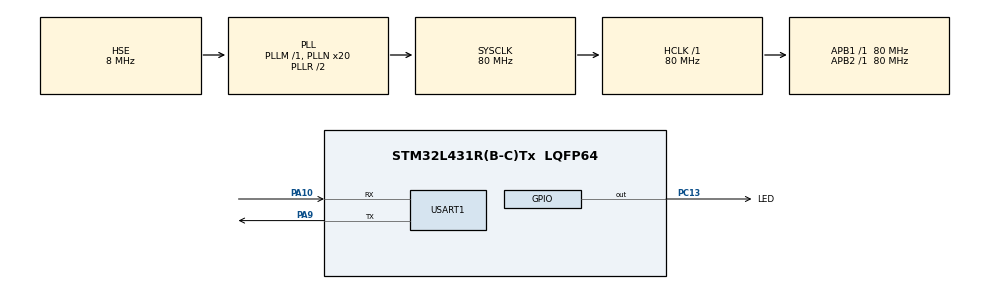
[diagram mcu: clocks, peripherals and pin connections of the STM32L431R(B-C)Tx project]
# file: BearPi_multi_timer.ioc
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Mcu.Family=STM32L4
Mcu.Name=STM32L431R(B-C)Tx
Mcu.Package=LQFP64
NVIC.PriorityGroup=NVIC_PRIORITYGROUP_4
PA10.Mode=Asynchronous
PA10.Signal=USART1_RX
PA13\ (JTMS-SWDIO).Mode=Serial_Wire
PA13\ (JTMS-SWDIO).Signal=SYS_JTMS-SWDIO
PA14\ (JTCK-SWCLK).Mode=Serial_Wire
PA14\ (JTCK-SWCLK).Signal=SYS_JTCK-SWCLK
PA9.Mode=Asynchronous
PA9.Signal=USART1_TX
PC13.GPIO_Label=LED
PC13.GPIO_Speed=GPIO_SPEED_FREQ_LOW
PC13.Signal=GPIO_Output
PH0-OSC_IN\ (PH0).Mode=HSE-External-Oscillator
PH0-OSC_IN\ (PH0).Signal=RCC_OSC_IN
PH1-OSC_OUT\ (PH1).Mode=HSE-External-Oscillator
PH1-OSC_OUT\ (PH1).Signal=RCC_OSC_OUT
ProjectManager.HeapSize=0x200
ProjectManager.StackSize=0x400
ProjectManager.TargetToolchain=MDK-ARM V5
RCC.ADCFreq_Value=32000000
RCC.AHBFreq_Value=80000000
RCC.APB1Freq_Value=80000000
RCC.APB1TimFreq_Value=80000000
RCC.APB2Freq_Value=80000000
RCC.APB2TimFreq_Value=80000000
RCC.CortexFreq_Value=80000000
RCC.HCLKFreq_Value=80000000
RCC.HSE_VALUE=8000000
RCC.HSI48_VALUE=48000000
RCC.HSI_VALUE=16000000
RCC.LSE_VALUE=32768
RCC.MSI_VALUE=4000000
RCC.PLLN=20
RCC.PLLSourceVirtual=RCC_PLLSOURCE_HSE
RCC.SYSCLKFreq_VALUE=80000000
RCC.SYSCLKSource=RCC_SYSCLKSOURCE_PLLCLK
RCC.VCOOutputFreq_Value=160000000
USART1.VirtualMode-Asynchronous=VM_ASYNC
board=custom

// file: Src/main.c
/* USER CODE BEGIN Header */
/**
  ******************************************************************************
  * @file           : main.c
  * @brief          : Main program body
  ******************************************************************************
  * @attention
  *
  * <h2><center>&copy; Copyright (c) 2020 STMicroelectronics.
  * All rights reserved.</center></h2>
  *
  * This software component is licensed by ST under BSD 3-Clause license,
  * the "License"; You may not use this file except in compliance with the
  * License. You may obtain a copy of the License at:
  *                        opensource.org/licenses/BSD-3-Clause
  *
  ******************************************************************************
  */
/* USER CODE END Header */

#include "main.h"
#include "usart.h"
#include "gpio.h"

/* USER CODE BEGIN PD */
/*用multi_timer创建的定时器1定时时间  单位:ms*/
#define TIMER_TIMEOUT_500MS 500
/*用multi_timer创建的定时器2定时时间  单位:ms*/
#define TIMER_TIMEOUT_1S 1000
/* USER CODE END PD */

/* USER CODE BEGIN PV */
Timer timer1 ;
Timer timer2 ;
/*用于定时10s的计数器*/
int Counter = 0 ;
/* USER CODE END PV */

void SystemClock_Config(void);
/* USER CODE BEGIN PFP */
/*定义重定向，这样才能使用printf函数*/
int fputc(int ch, FILE *file)
{
    return HAL_UART_Transmit(&huart1, (uint8_t *)&ch, 1, 1000);
}

/*multi_timer回调函数1调用*/
void timer1_callback(void)
{
    /*LED灯电平翻转*/
    //LED = !LED ;
    HAL_GPIO_TogglePin(LED_GPIO_Port, LED_Pin);
}
/*multi_timer回调函数2调用*/
void timer2_callback(void)
{
    /*当计数器到达10次以后删除所有创建的软件定时器
      计数器清0，将LED电平置为1，常亮
    */
    ++Counter ;

    if(Counter == 10)
    {
        Counter = 0 ;
        //LED = 1 ;
        HAL_GPIO_WritePin(LED_GPIO_Port, LED_Pin, GPIO_PIN_SET);
        printf("LED灯常亮\n");
        timer_stop(&timer1);
        printf("关闭定时器1\n");
        timer_stop(&timer2);
        printf("关闭定时器2\n");
    }
}
/* USER CODE END PFP */

int main(void)
{

    /* MCU Configuration--------------------------------------------------------*/

    /* Reset of all peripherals, Initializes the Flash interface and the Systick. */
    HAL_Init();

    /* Configure the system clock */
    SystemClock_Config();

    /* Initialize all configured peripherals */
    MX_GPIO_Init();
    MX_USART1_UART_Init();
    /* USER CODE BEGIN 2 */
    timer_init(&timer1, timer1_callback, TIMER_TIMEOUT_500MS, TIMER_TIMEOUT_500MS);
    timer_init(&timer2, timer2_callback, TIMER_TIMEOUT_1S, TIMER_TIMEOUT_1S);
    timer_start(&timer1);
    timer_start(&timer2);
    /* USER CODE END 2 */

    /* Infinite loop */
    while (1)
    {

        /* USER CODE BEGIN 3 */
        timer_loop();
    }

    /* USER CODE END 3 */
}

void SystemClock_Config(void)
{
    RCC_OscInitTypeDef RCC_OscInitStruct = {0};
    RCC_ClkInitTypeDef RCC_ClkInitStruct = {0};
    RCC_PeriphCLKInitTypeDef PeriphClkInit = {0};

    /** Initializes the CPU, AHB and APB busses clocks
    */
    RCC_OscInitStruct.OscillatorType = RCC_OSCILLATORTYPE_HSE;
    RCC_OscInitStruct.HSEState = RCC_HSE_ON;
    RCC_OscInitStruct.PLL.PLLState = RCC_PLL_ON;
    RCC_OscInitStruct.PLL.PLLSource = RCC_PLLSOURCE_HSE;
    RCC_OscInitStruct.PLL.PLLM = 1;
    RCC_OscInitStruct.PLL.PLLN = 20;
    RCC_OscInitStruct.PLL.PLLP = RCC_PLLP_DIV7;
    RCC_OscInitStruct.PLL.PLLQ = RCC_PLLQ_DIV2;
    RCC_OscInitStruct.PLL.PLLR = RCC_PLLR_DIV2;

    if (HAL_RCC_OscConfig(&RCC_OscInitStruct) != HAL_OK)
    {
        Error_Handler();
    }

    /** Initializes the CPU, AHB and APB busses clocks
    */
    RCC_ClkInitStruct.ClockType = RCC_CLOCKTYPE_HCLK | RCC_CLOCKTYPE_SYSCLK
                                  | RCC_CLOCKTYPE_PCLK1 | RCC_CLOCKTYPE_PCLK2;
    RCC_ClkInitStruct.SYSCLKSource = RCC_SYSCLKSOURCE_PLLCLK;
    RCC_ClkInitStruct.AHBCLKDivider = RCC_SYSCLK_DIV1;
    RCC_ClkInitStruct.APB1CLKDivider = RCC_HCLK_DIV1;
    RCC_ClkInitStruct.APB2CLKDivider = RCC_HCLK_DIV1;

    if (HAL_RCC_ClockConfig(&RCC_ClkInitStruct, FLASH_LATENCY_4) != HAL_OK)
    {
        Error_Handler();
    }

    PeriphClkInit.PeriphClockSelection = RCC_PERIPHCLK_USART1;
    PeriphClkInit.Usart1ClockSelection = RCC_USART1CLKSOURCE_PCLK2;

    if (HAL_RCCEx_PeriphCLKConfig(&PeriphClkInit) != HAL_OK)
    {
        Error_Handler();
    }

    /** Configure the main internal regulator output voltage
    */
    if (HAL_PWREx_ControlVoltageScaling(PWR_REGULATOR_VOLTAGE_SCALE1) != HAL_OK)
    {
        Error_Handler();
    }
}

void Error_Handler(void)
{
}

/************************ (C) COPYRIGHT STMicroelectronics *****END OF FILE****/
